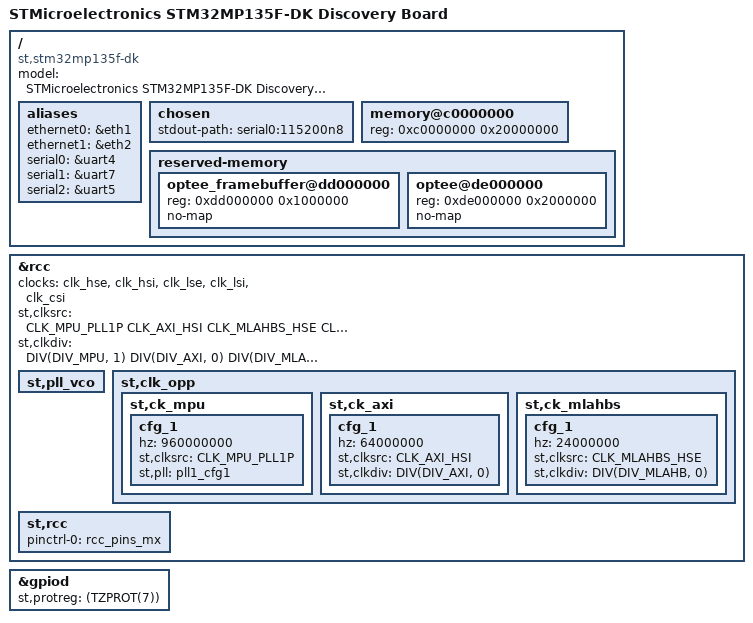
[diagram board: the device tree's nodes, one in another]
// SPDX-License-Identifier: (GPL-2.0+ OR BSD-3-Clause)
/*
 * Copyright (C) MYiR 2022 - All Rights Reserved
 * Author: Alexhu <fan.hu@myirtech.com> for MYiR.
 */

/dts-v1/;

#include "myb-stm32mp135x-base.dtsi"

/ {
	model = "STMicroelectronics STM32MP135F-DK Discovery Board";
	compatible = "st,stm32mp135f-dk", "st,stm32mp135";

	aliases {
		ethernet0 = &eth1;
		ethernet1 = &eth2;
		serial0 = &uart4;
		serial1 = &uart7;
		serial2 = &uart5;
	};

	chosen {
		#address-cells = <1>;
		#size-cells = <1>;
		ranges;
		stdout-path = "serial0:115200n8";
	};

	memory@c0000000 {
		device_type = "memory";
		reg = <0xc0000000 0x20000000>;
	};

	reserved-memory {
		#address-cells = <1>;
		#size-cells = <1>;
		ranges;

		optee_framebuffer@dd000000 {
			reg = <0xdd000000 0x1000000>;
			no-map;
		};

		optee@de000000 {
			reg = <0xde000000 0x2000000>;
			no-map;
		};
	};

};


&rcc {
	status = "okay";
	clocks = <&clk_hse>, <&clk_hsi>, <&clk_lse>, <&clk_lsi>, <&clk_csi>;
	clock-names = "clk-hse", "clk-hsi", "clk-lse", "clk-lsi", "clk-csi";
	st,clksrc = < CLK_MPU_PLL1P
		CLK_AXI_HSI
		CLK_MLAHBS_HSE
		CLK_RTC_LSE
		CLK_MCO1_HSE
		CLK_MCO2_DISABLED
		CLK_CKPER_DISABLED
		CLK_STGEN_HSE
	>;

	st,clkdiv = <
		DIV(DIV_MPU, 1)
		DIV(DIV_AXI, 0)
		DIV(DIV_MLAHB, 0)
		DIV(DIV_APB1, 1)
		DIV(DIV_APB2, 1)
		DIV(DIV_APB3, 1)
		DIV(DIV_APB4, 0)
		DIV(DIV_APB5, 0)
		DIV(DIV_APB6, 1)
		DIV(DIV_RTC, 0)
		DIV(DIV_MCO1, 1)
		DIV(DIV_MCO2, 0)
	>;
	st,pll_vco {
		/* USER CODE BEGIN rcc_st-pll_vco */
		/* USER CODE END rcc_st-pll_vco */
	};

	st,clk_opp {
		/* CK_MPU clock config for MP13 */
		st,ck_mpu {

			cfg_1 {
				hz = < 960000000 >;
				st,clksrc = < CLK_MPU_PLL1P >;
				st,pll = < &pll1_cfg1 >;
			};
			/* USER CODE BEGIN rcc_st-ck_mpu */
			/* USER CODE END rcc_st-ck_mpu */
		};

		/* CK_AXI clock config for MP13 */
		st,ck_axi {

			cfg_1 {
				hz = < 64000000 >;
				st,clksrc = < CLK_AXI_HSI >;
				st,clkdiv = < DIV(DIV_AXI, 0) >;
			};
			/* USER CODE BEGIN rcc_st-ck_axi */
			/* USER CODE END rcc_st-ck_axi */
		};

		/* CK_MLAHBS clock config for MP13 */
		st,ck_mlahbs {

			cfg_1 {
				hz = < 24000000 >;
				st,clksrc = < CLK_MLAHBS_HSE >;
				st,clkdiv = < DIV(DIV_MLAHB, 0) >;
			};

			/* USER CODE BEGIN rcc_st-ck_mlahbs */
			/* USER CODE END rcc_st-ck_mlahbs */
		};
    };
    
    st,rcc{
        pinctrl-names = "default";
        pinctrl-0 = <&rcc_pins_mx>;
        status = "okay";
    };
};


&gpiod {
    st,protreg = < (TZPROT(7)) >;
}

